# MSP430FR2476 register map
Vendor: msp430gen; File version: v0.4.0-28-gb0087ce-dirty
Registers are 16-bit, read-write, reset 0x0 unless marked. A register's access mark holds for its fields unless they carry their own. Offsets are from the block's base; [hi:lo] are bit positions; {n}, {i} and the like mark numbered series; 'fields as' and 'values as' point back to an identical list.

## SFR
Base 0x00000100
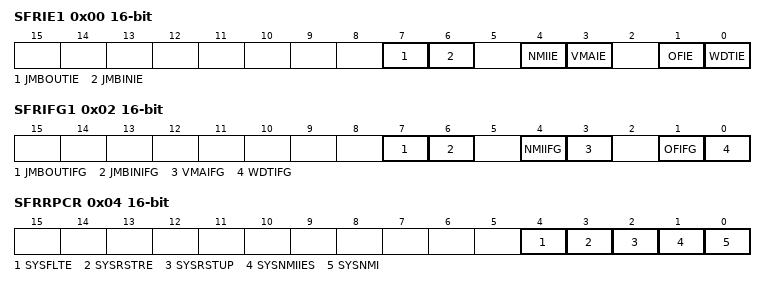
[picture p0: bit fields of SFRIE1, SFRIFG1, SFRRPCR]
0x00 SFRIE1 — Interrupt Enable
  [all] fields
    0=DISABLE (Interrupts disabled); 1=ENABLE (Interrupts enabled)
  [7] JMBOUTIE — JTAG mailbox output interrupt enable
  [6] JMBINIE — JTAG mailbox input interrupt enable
  [4] NMIIE — NMI pin interrupt enable
  [3] VMAIE — Vacant memory access interrupt enable
  [1] OFIE — Oscillator fault interrupt enable
  [0] WDTIE — Watchdog timer interrupt enable
0x02 SFRIFG1 — Interrupt Flag
  [7] JMBOUTIFG — JTAG mailbox output interrupt flag
    0=No interrupt pending. When in 16-bit mode (JMBMODE = 0), this bit is cleared automatically when JMBO0 has been written with a new message to the JTAG module by the CPU. When in 32-bit mode (JMBMODE = 1), this bit is cleared automatically when both JMBO0 and JMBO1 have been written with new messages to the JTAG module by the CPU. This bit is also cleared when the associated vector in SYSUNIV has been read.; 1=Interrupt pending. JMBO registers are ready for new messages. In 16-bit mode (JMBMODE = 0), JMBO0 has been received by the JTAG module and is ready for a new message from the CPU. In 32-bit mode (JMBMODE = 1), JMBO0 and JMBO1 have been received by the JTAG module and are ready for new messages from the CPU.
  [6] JMBINIFG — JTAG mailbox input interrupt flag
    0=No interrupt pending. When in 16-bit mode (JMBMODE = 0), this bit is cleared automatically when JMBI0 is read by the CPU. When in 32-bit mode (JMBMODE = 1), this bit is cleared automatically when both JMBI0 and JMBI1 have been read by the CPU. This bit is also cleared when the associated vector in SYSUNIV has been read; 1=Interrupt pending. A message is waiting in the JMBIN registers. In 16-bit mode (JMBMODE = 0) when JMBI0 has been written by the JTAG module. In 32-bit mode (JMBMODE = 1) when JMBI0 and JMBI1 have been written by the JTAG module.
  [4] NMIIFG — NMI pin interrupt flag
    0=No interrupt pending; 1=Interrupt pending
  [3] VMAIFG — Vacant memory access interrupt flag
    0=No interrupt pending; 1=Interrupt pending
  [1] OFIFG — Oscillator fault interrupt flag
    0=No interrupt pending; 1=Interrupt pending
  [0] WDTIFG — Watchdog timer interrupt flag
    0=No interrupt pending; 1=Interrupt pending
0x04 SFRRPCR — Reset Pin Control
  [4] SYSFLTE — Reset pin filter enable
    0=DISABLED (Digital filter on reset pin is disabled); 1=ENABLED (Digital filter on reset pin is enabled)
  [3] SYSRSTRE — Reset pin resistor enable
    0=DISABLE (Pullup or pulldown resistor at the RST/NMI pin is disabled); 1=ENABLE (Pullup or pulldown resistor at the RST/NMI pin is enabled)
  [2] SYSRSTUP — Reset resistor pin pullup or pulldown
    0=PULLDOWN (Pulldown is selected); 1=PULLUP (Pullup is selected)
  [1] SYSNMIIES — NMI edge select
    0=RISING (NMI on rising edge); 1=FALLING (NMI on falling edge)
  [0] SYSNMI — NMI select
    0=RESET (Reset function); 1=NMI (NMI function)

## FRCTL
Base 0x000001A0
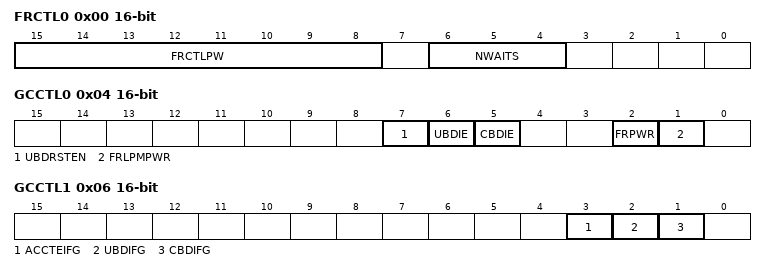
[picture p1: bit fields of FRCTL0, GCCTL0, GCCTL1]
0x00 FRCTL0 — FRAM Controller Control Register 0
  [15:8] FRCTLPW — FRCTLPW password
    on read: 150=PASSWORD (Value always read from the FRCTL0 password) | on write: 165=PASSWORD (Value which must be written to the FRCTL0 password)
  [6:4] NWAITS — Wait state numbers
    0=WAIT0 (No wait state); 1=WAIT1 (1 wait state); {v}=WAIT{v} ({v} wait states) (v=2..7)
0x01 FRCTL0_H 8-bit (alternate view of FRCTL0) — FRAM Controller Control Register 0, upper byte
  [7:0] FRCTLPW — FRAM controller password
    on read: 150=PASSWORD (Value always read from the FRCTL0 password) | on write: 0=LOCK (Locks the FRAM controller registers again); 165=PASSWORD (Unlocks the FRAM controller registers)
0x04 GCCTL0 — General Control Register 0
  [7] UBDRSTEN — Enable Power Up Clear (PUC) reset for the uncorrectable bit error detection flag (UBDIFG)
    0=PUC not initiated on uncorrectable bit error detection flag; 1=PUC initiated on uncorrectable bit error detection flag. Generates vector in SYSRSTIV. Clear the UBDIE bit.
  [6] UBDIE — Enable NMI event for the uncorrectable bit error detection flag (UBDIFG)
    0=Disable NMI for the uncorrectable bit error detection flag (UBDIFG); 1=Enable NMI for the uncorrectable bit error detection flag (UBDIFG). Generates vector in SYSSNIV. Clear the UBDRSTEN bit.
  [5] CBDIE — Enable NMI event for the correctable bit error detection flag (CBDIFG)
    0=Disable NMI for the correctable bit error detection flag (CBDIFG); 1=Disable NMI for the correctable bit error detection flag (CBDIFG). Generates vector in SYSSNIV.
  [2] FRPWR — FRAM Memory Power Control Request
    0=DISABLED (FRAM power supply disabled); 1=ENABLED (FRAM power supply enabled)
  [1] FRLPMPWR ro — Enables FRAM auto power up after LPM
    0=FRAM startup is delayed to the first FRAM access after exit from LPM; 1=FRAM is powered up immediately on exit from LPM
0x06 GCCTL1 — General Control Register 1
  [3] ACCTEIFG — Access time error flag
    0=No interrupt pending; 1=Interrupt pending. Can be cleared by writing '0' or by reading SYSSNIV when it is the highest pending interrupt.
  [2] UBDIFG — FRAM uncorrectable bit error detection flag
    values as ACCTEIFG
  [1] CBDIFG — FRAM correctable bit error detection flag
    0=No interrupt is pending; 1=Interrupt pending. Can be cleared by writing '0' or by reading SYSSNIV if it is the highest pending interrupt.
